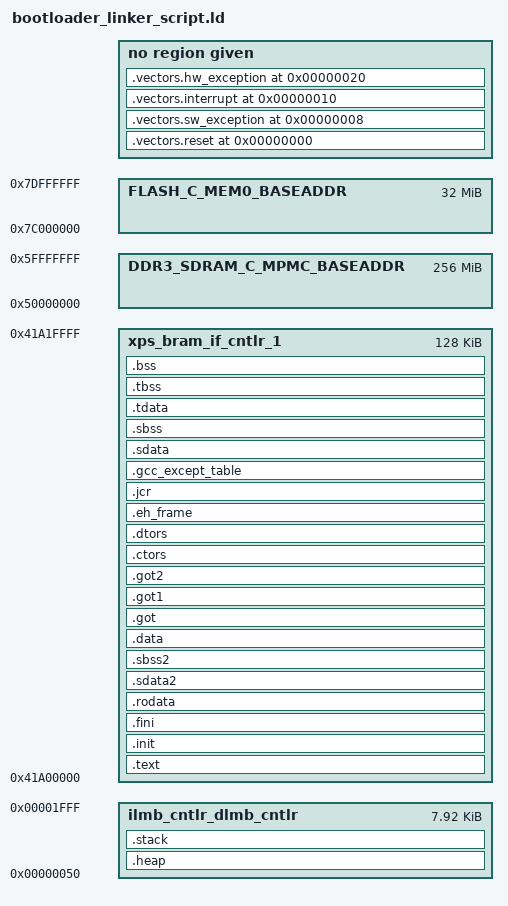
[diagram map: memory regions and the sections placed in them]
/*******************************************************************/
/*                                                                 */
/* This file is automatically generated by linker script generator.*/
/*                                                                 */
/* Version: Xilinx EDK 11.3 EDK_LS3.49                                */
/*                                                                 */
/* Copyright (c) 2004 Xilinx, Inc.  All rights reserved.           */
/*                                                                 */
/* Description : MicroBlaze Linker Script                          */
/*                                                                 */
/*******************************************************************/

_STACK_SIZE = DEFINED(_STACK_SIZE) ? _STACK_SIZE : 0x1000;
_HEAP_SIZE = DEFINED(_HEAP_SIZE) ? _HEAP_SIZE : 0x400;

/* Define Memories in the system */

MEMORY
{
   ilmb_cntlr_dlmb_cntlr : ORIGIN = 0x00000050, LENGTH = 0x00001FB0
   xps_bram_if_cntlr_1 : ORIGIN = 0x41A00000, LENGTH = 0x00020000
   DDR3_SDRAM_C_MPMC_BASEADDR : ORIGIN = 0x50000000, LENGTH = 0x10000000
   FLASH_C_MEM0_BASEADDR : ORIGIN = 0x7C000000, LENGTH = 0x02000000
}

/* Specify the default entry point to the program */

ENTRY(_start)

/* Define the sections, and where they are mapped in memory */

SECTIONS
{
.vectors.reset 0x00000000 : {
   *(.vectors.reset)
} 

.vectors.sw_exception 0x00000008 : {
   *(.vectors.sw_exception)
} 

.vectors.interrupt 0x00000010 : {
   *(.vectors.interrupt)
} 

.vectors.hw_exception 0x00000020 : {
   *(.vectors.hw_exception)
} 

.text : {
   *(.text)
   *(.text.*)
   *(.gnu.linkonce.t.*)
} > xps_bram_if_cntlr_1

.init : {
   KEEP (*(.init))
} > xps_bram_if_cntlr_1

.fini : {
   KEEP (*(.fini))
} > xps_bram_if_cntlr_1

.rodata : {
   __rodata_start = .;
   *(.rodata)
   *(.rodata.*)
   *(.gnu.linkonce.r.*)
   __rodata_end = .;
} > xps_bram_if_cntlr_1

.sdata2 : {
   . = ALIGN(8);
   __sdata2_start = .;
   *(.sdata2)
   *(.sdata2.*)
   *(.gnu.linkonce.s2.*)
   . = ALIGN(8);
   __sdata2_end = .;
} > xps_bram_if_cntlr_1

.sbss2 : {
   __sbss2_start = .;
   *(.sbss2)
   *(.sbss2.*)
   *(.gnu.linkonce.sb2.*)
   __sbss2_end = .;
} > xps_bram_if_cntlr_1

.data : {
   . = ALIGN(4);
   __data_start = .;
   *(.data)
   *(.data.*)
   *(.gnu.linkonce.d.*)
   __data_end = .;
} > xps_bram_if_cntlr_1

.got : {
   *(.got)
} > xps_bram_if_cntlr_1

.got1 : {
   *(.got1)
} > xps_bram_if_cntlr_1

.got2 : {
   *(.got2)
} > xps_bram_if_cntlr_1

.ctors : {
   __CTOR_LIST__ = .;
   ___CTORS_LIST___ = .;
   KEEP (*crtbegin.o(.ctors))
   KEEP (*(EXCLUDE_FILE(*crtend.o) .ctors))
   KEEP (*(SORT(.ctors.*)))
   KEEP (*(.ctors))
   __CTOR_END__ = .;
   ___CTORS_END___ = .;
} > xps_bram_if_cntlr_1

.dtors : {
   __DTOR_LIST__ = .;
   ___DTORS_LIST___ = .;
   KEEP (*crtbegin.o(.dtors))
   KEEP (*(EXCLUDE_FILE(*crtend.o) .dtors))
   KEEP (*(SORT(.dtors.*)))
   KEEP (*(.dtors))
   __DTOR_END__ = .;
   ___DTORS_END___ = .;
} > xps_bram_if_cntlr_1

.eh_frame : {
   *(.eh_frame)
} > xps_bram_if_cntlr_1

.jcr : {
   *(.jcr)
} > xps_bram_if_cntlr_1

.gcc_except_table : {
   *(.gcc_except_table)
} > xps_bram_if_cntlr_1

.sdata : {
   . = ALIGN(8);
   __sdata_start = .;
   *(.sdata)
   *(.sdata.*)
   *(.gnu.linkonce.s.*)
   __sdata_end = .;
} > xps_bram_if_cntlr_1

.sbss : {
   . = ALIGN(4);
   __sbss_start = .;
   *(.sbss)
   *(.sbss.*)
   *(.gnu.linkonce.sb.*)
   . = ALIGN(8);
   __sbss_end = .;
} > xps_bram_if_cntlr_1

.tdata : {
   __tdata_start = .;
   *(.tdata)
   *(.tdata.*)
   *(.gnu.linkonce.td.*)
   __tdata_end = .;
} > xps_bram_if_cntlr_1

.tbss : {
   __tbss_start = .;
   *(.tbss)
   *(.tbss.*)
   *(.gnu.linkonce.tb.*)
   __tbss_end = .;
} > xps_bram_if_cntlr_1

.bss : {
   . = ALIGN(4);
   __bss_start = .;
   *(.bss)
   *(.bss.*)
   *(.gnu.linkonce.b.*)
   *(COMMON)
   . = ALIGN(4);
   __bss_end = .;
} > xps_bram_if_cntlr_1

_SDA_BASE_ = __sdata_start + ((__sbss_end - __sdata_start) / 2 );

_SDA2_BASE_ = __sdata2_start + ((__sbss2_end - __sdata2_start) / 2 );

/* Generate Stack and Heap definitions */

.heap : {
   . = ALIGN(8);
   _heap = .;
   _heap_start = .;
   . += _HEAP_SIZE;
   _heap_end = .;
} > ilmb_cntlr_dlmb_cntlr

.stack : {
   _stack_end = .;
   . += _STACK_SIZE;
   . = ALIGN(8);
   _stack = .;
   __stack = _stack;
} > ilmb_cntlr_dlmb_cntlr

}

